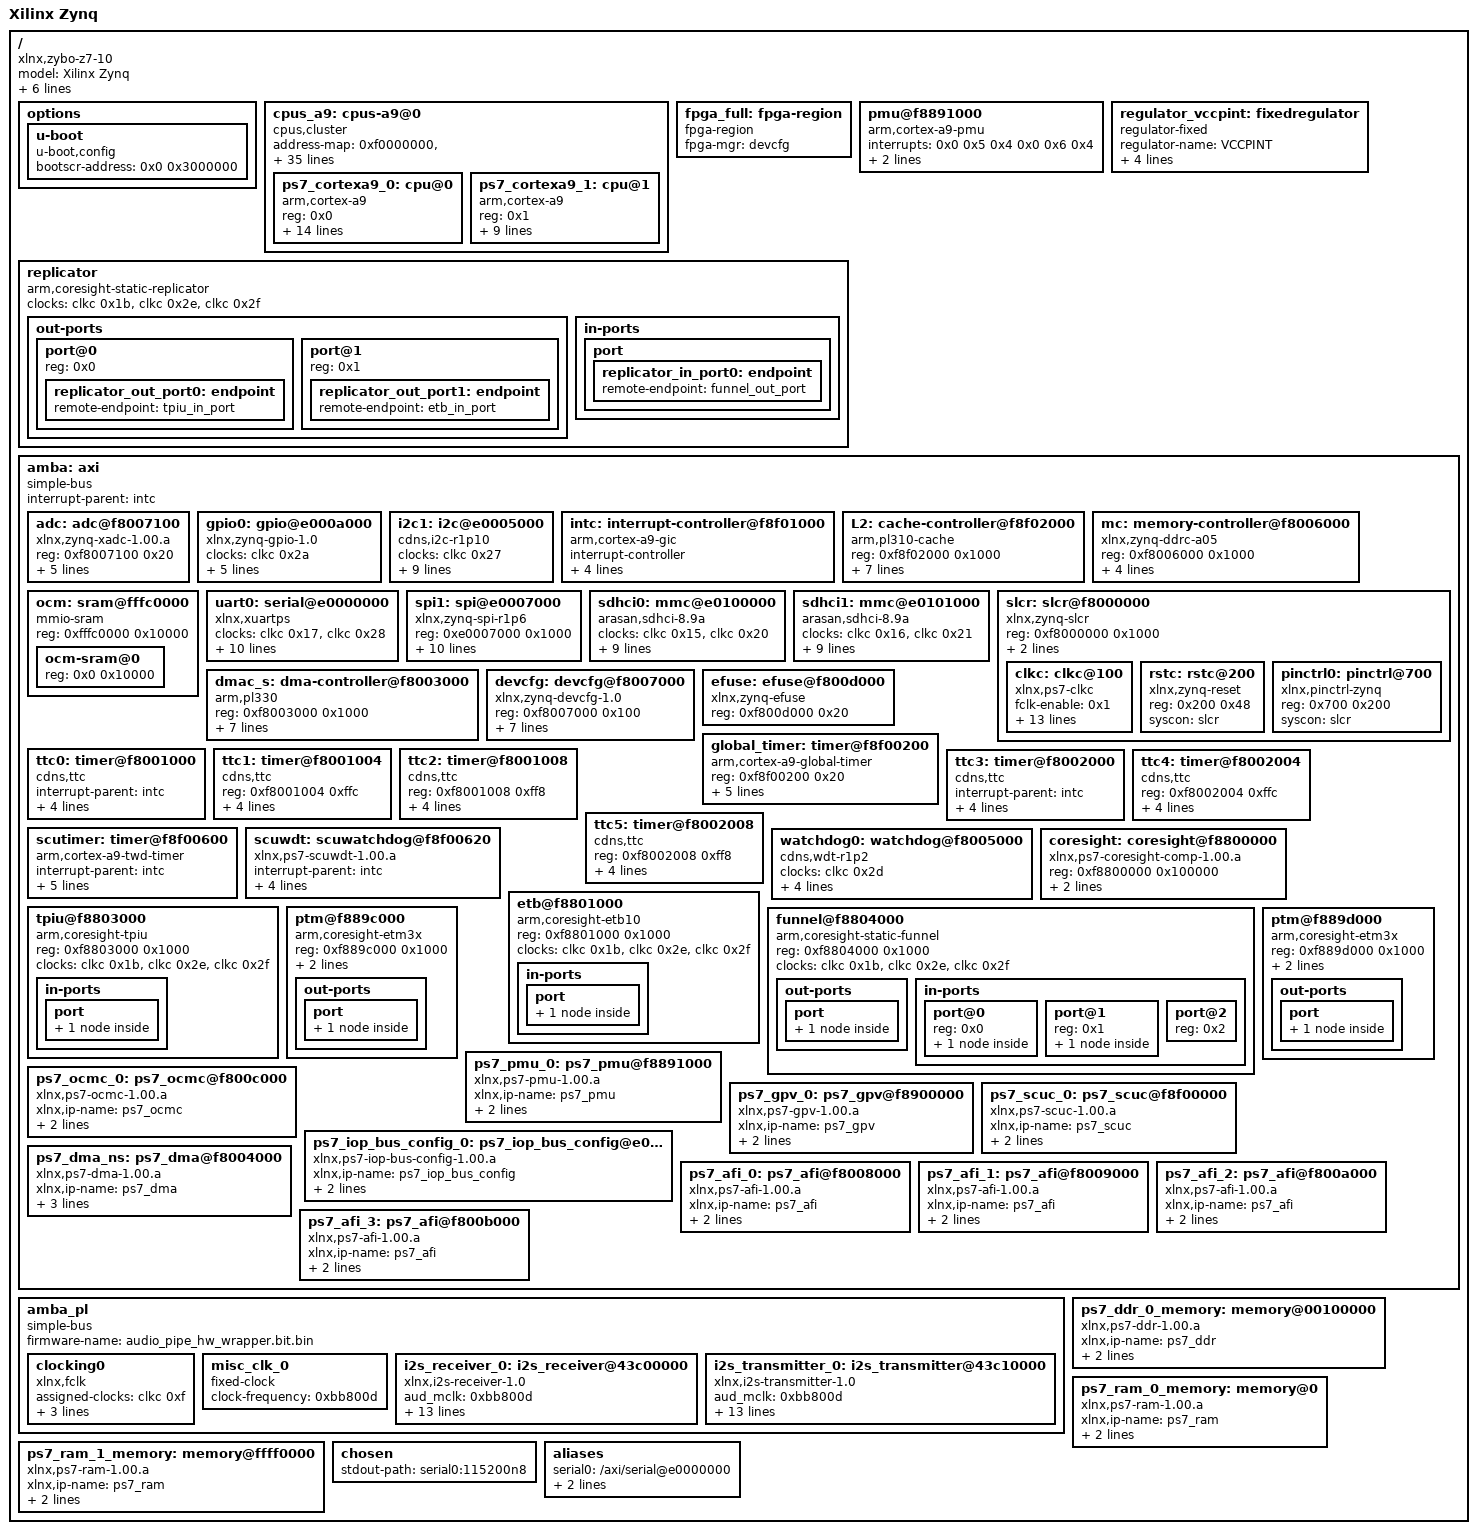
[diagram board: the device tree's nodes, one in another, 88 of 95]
/dts-v1/;
/ {
        #address-cells = <0x1>;
        #size-cells = <0x1>;
        compatible = "xlnx,zybo-z7-10";
        model = "Xilinx Zynq";
        board = "zybo-z7-10";
        device_id = "7z010";
        slrcount = <0x1>;
        family = "Zynq";
        speed_grade = "1";
        pruned-sdt = <0x1>;

        options {

                u-boot {
                        compatible = "u-boot,config";
                        bootscr-address = <0x0 0x3000000>;
                };
        };

        cpus_a9: cpus-a9@0 {
                phandle = <0x30>;
                #address-cells = <0x1>;
                #size-cells = <0x0>;
                compatible = "cpus,cluster";
                address-map = <0xf0000000 &amba 0xf0000000 0x10000000>,
                 <0x100000 &ps7_ddr_0_memory 0x100000 0x1ff00000>,
                 <0x0 &ps7_ram_0_memory 0x0 0x30000>,
                 <0xffff0000 &ps7_ram_1_memory 0xffff0000 0xfe00>,
                 <0x43c00000 &i2s_receiver_0 0x43c00000 0x10000>,
                 <0x43c10000 &i2s_transmitter_0 0x43c10000 0x10000>,
                 <0xf8008000 &ps7_afi_0 0xf8008000 0x1000>,
                 <0xf8009000 &ps7_afi_1 0xf8009000 0x1000>,
                 <0xf800a000 &ps7_afi_2 0xf800a000 0x1000>,
                 <0xf800b000 &ps7_afi_3 0xf800b000 0x1000>,
                 <0xf8800000 &coresight 0xf8800000 0x100000>,
                 <0xf8006000 &mc 0xf8006000 0x1000>,
                 <0xf8007000 &devcfg 0xf8007000 0x100>,
                 <0xf8004000 &ps7_dma_ns 0xf8004000 0x1000>,
                 <0xf8003000 &dmac_s 0xf8003000 0x1000>,
                 <0xf8f00200 &global_timer 0xf8f00200 0x100>,
                 <0xf8900000 &ps7_gpv_0 0xf8900000 0x100000>,
                 <0xe0005000 &i2c1 0xe0005000 0x1000>,
                 <0xf8f01000 &intc 0xf8f01000 0x1000>,
                 <0xe0200000 &ps7_iop_bus_config_0 0xe0200000 0x1000>,
                 <0xf8f02000 &L2 0xf8f02000 0x1000>,
                 <0xf800c000 &ps7_ocmc_0 0xf800c000 0x1000>,
                 <0xf8891000 &ps7_pmu_0 0xf8891000 0x1000>,
                 <0xf8f00000 &ps7_scuc_0 0xf8f00000 0xfd>,
                 <0xf8f00600 &scutimer 0xf8f00600 0x20>,
                 <0xf8f00620 &scuwdt 0xf8f00620 0xe0>,
                 <0xe0100000 &sdhci0 0xe0100000 0x1000>,
                 <0xe0101000 &sdhci1 0xe0101000 0x1000>,
                 <0xf8000000 &slcr 0xf8000000 0x1000>,
                 <0xe0007000 &spi1 0xe0007000 0x1000>,
                 <0xe0000000 &uart0 0xe0000000 0x1000>,
                 <0xf8007100 &adc 0xf8007100 0x21>;
                #ranges-address-cells = <0x1>;
                #ranges-size-cells = <0x1>;

                ps7_cortexa9_0: cpu@0 {
                        phandle = <0x2b>;
                        compatible = "arm,cortex-a9";
                        device_type = "cpu";
                        reg = <0x0>;
                        clocks = <&clkc 0x3>;
                        clock-latency = <0x3e8>;
                        cpu0-supply = <&regulator_vccpint>;
                        operating-points = <0xa2c2b 0xf4240 0x51616 0xf4240>;
                        xlnx,i-cache-size = <0x8000>;
                        xlnx,d-cache-line-size = <0x14>;
                        xlnx,i-cache-line-size = <0x14>;
                        xlnx,cpu-1x-clk-freq-hz = <0x69f6bcb>;
                        xlnx,ip-name = "ps7_cortexa9";
                        xlnx,d-cache-size = <0x8000>;
                        xlnx,num-cores = <0x2>;
                        xlnx,cpu-clk-freq-hz = <0x27bc86bf>;
                        bus-handle = <0x1>;
                };

                ps7_cortexa9_1: cpu@1 {
                        phandle = <0x2d>;
                        compatible = "arm,cortex-a9";
                        device_type = "cpu";
                        reg = <0x1>;
                        clocks = <&clkc 0x3>;
                        xlnx,i-cache-size = <0x8000>;
                        xlnx,d-cache-line-size = <0x14>;
                        xlnx,i-cache-line-size = <0x14>;
                        xlnx,cpu-1x-clk-freq-hz = <0x69f6bcb>;
                        xlnx,ip-name = "ps7_cortexa9";
                        xlnx,d-cache-size = <0x8000>;
                        xlnx,cpu-clk-freq-hz = <0x27bc86bf>;
                        bus-handle = <0x1>;
                };
        };

        fpga_full: fpga-region {
                phandle = <0x31>;
                compatible = "fpga-region";
                fpga-mgr = <&devcfg>;
                #address-cells = <0x1>;
                #size-cells = <0x1>;
                ranges;
        };

        pmu@f8891000 {
                compatible = "arm,cortex-a9-pmu";
                interrupts = <0x0 0x5 0x4 0x0 0x6 0x4>;
                interrupt-parent = <&intc>;
                reg = <0xf8891000 0x1000 0xf8893000 0x1000>;
        };

        regulator_vccpint: fixedregulator {
                phandle = <0x22>;
                compatible = "regulator-fixed";
                regulator-name = "VCCPINT";
                regulator-min-microvolt = <0xf4240>;
                regulator-max-microvolt = <0xf4240>;
                regulator-boot-on;
                regulator-always-on;
        };

        replicator {
                compatible = "arm,coresight-static-replicator";
                clocks = <&clkc 0x1b>,
                 <&clkc 0x2e>,
                 <&clkc 0x2f>;
                clock-names = "apb_pclk", "dbg_trc", "dbg_apb";

                out-ports {
                        #address-cells = <0x1>;
                        #size-cells = <0x0>;

                        port@0 {
                                reg = <0x0>;

                                replicator_out_port0: endpoint {
                                        phandle = <0x27>;
                                        remote-endpoint = <&tpiu_in_port>;
                                };
                        };

                        port@1 {
                                reg = <0x1>;

                                replicator_out_port1: endpoint {
                                        phandle = <0x26>;
                                        remote-endpoint = <&etb_in_port>;
                                };
                        };
                };

                in-ports {

                        port {

                                replicator_in_port0: endpoint {
                                        phandle = <0x28>;
                                        remote-endpoint = <&funnel_out_port>;
                                };
                        };
                };
        };

        amba: axi {
                phandle = <0x1>;
                bootph-all;
                compatible = "simple-bus";
                #address-cells = <0x1>;
                #size-cells = <0x1>;
                interrupt-parent = <&intc>;
                ranges;

                adc: adc@f8007100 {
                        phandle = <0x20>;
                        compatible = "xlnx,zynq-xadc-1.00.a";
                        reg = <0xf8007100 0x20>;
                        interrupts = <0x0 0x7 0x4>;
                        interrupt-parent = <&intc>;
                        clocks = <&clkc 0xc>;
                        status = "okay";
                        xlnx,ip-name = "ps7_xadc";
                        xlnx,name = "ps7_xadc_0";
                };

                gpio0: gpio@e000a000 {
                        phandle = <0x34>;
                        compatible = "xlnx,zynq-gpio-1.0";
                        #gpio-cells = <0x2>;
                        clocks = <&clkc 0x2a>;
                        gpio-controller;
                        interrupt-controller;
                        #interrupt-cells = <0x2>;
                        interrupt-parent = <&intc>;
                        interrupts = <0x0 0x14 0x4>;
                        reg = <0xe000a000 0x1000>;
                };

                i2c1: i2c@e0005000 {
                        phandle = <0x12>;
                        compatible = "cdns,i2c-r1p10";
                        status = "okay";
                        clocks = <&clkc 0x27>;
                        interrupt-parent = <&intc>;
                        interrupts = <0x0 0x30 0x4>;
                        clock-frequency = <0x61a80>;
                        reg = <0xe0005000 0x1000>;
                        #address-cells = <0x1>;
                        #size-cells = <0x0>;
                        xlnx,has-interrupt = <0x0>;
                        xlnx,clock-freq = <0x69f6bcb>;
                        xlnx,i2c-clk-freq-hz = <0x69f6bcb>;
                        xlnx,ip-name = "ps7_i2c";
                        xlnx,name = "ps7_i2c_1";
                };

                intc: interrupt-controller@f8f01000 {
                        phandle = <0x13>;
                        compatible = "arm,cortex-a9-gic";
                        #interrupt-cells = <0x3>;
                        interrupt-controller;
                        reg = <0xf8f01000 0x1000 0xf8f00100 0x100>;
                        status = "okay";
                        xlnx,irq-f2p-mode = "DIRECT";
                        xlnx,ip-name = "ps7_intc_dist";
                        xlnx,name = "ps7_intc_dist_0";
                };

                L2: cache-controller@f8f02000 {
                        phandle = <0x15>;
                        compatible = "arm,pl310-cache";
                        reg = <0xf8f02000 0x1000>;
                        interrupts = <0x0 0x2 0x4>;
                        arm,data-latency = <0x3 0x2 0x2>;
                        arm,tag-latency = <0x2 0x2 0x2>;
                        cache-unified;
                        cache-level = <0x2>;
                        status = "okay";
                        xlnx,ip-name = "ps7_pl310";
                        xlnx,name = "ps7_pl310_0";
                };

                mc: memory-controller@f8006000 {
                        phandle = <0xc>;
                        compatible = "xlnx,zynq-ddrc-a05";
                        reg = <0xf8006000 0x1000>;
                        status = "okay";
                        xlnx,ddr-clk-freq-hz = <0x1fca057e>;
                        xlnx,ip-name = "ps7_ddrc";
                        xlnx,has-ecc = <0x0>;
                        xlnx,name = "ps7_ddrc_0";
                };

                ocm: sram@fffc0000 {
                        phandle = <0x36>;
                        compatible = "mmio-sram";
                        reg = <0xfffc0000 0x10000>;
                        #address-cells = <0x1>;
                        #size-cells = <0x1>;
                        ranges = <0x0 0xfffc0000 0x10000>;

                        ocm-sram@0 {
                                reg = <0x0 0x10000>;
                        };
                };

                uart0: serial@e0000000 {
                        phandle = <0x1f>;
                        compatible = "xlnx,xuartps", "cdns,uart-r1p8";
                        status = "okay";
                        clocks = <&clkc 0x17>,
                         <&clkc 0x28>;
                        clock-names = "uart_clk", "pclk";
                        reg = <0xe0000000 0x1000>;
                        interrupts = <0x0 0x1b 0x4>;
                        interrupt-parent = <&intc>;
                        xlnx,clock-freq = <0x5f5e100>;
                        xlnx,has-modem = <0x0>;
                        xlnx,ip-name = "ps7_uart";
                        cts-override;
                        port-number = <0x0>;
                        xlnx,uart-clk-freq-hz = <0x5f5e100>;
                        xlnx,name = "ps7_uart_0";
                };

                spi1: spi@e0007000 {
                        phandle = <0x1e>;
                        compatible = "xlnx,zynq-spi-r1p6";
                        reg = <0xe0007000 0x1000>;
                        status = "okay";
                        interrupt-parent = <&intc>;
                        interrupts = <0x0 0x31 0x4>;
                        clocks = <&clkc 0x1a>,
                         <&clkc 0x23>;
                        clock-names = "ref_clk", "pclk";
                        #address-cells = <0x1>;
                        #size-cells = <0x0>;
                        xlnx,has-ss0 = <0x1>;
                        xlnx,ip-name = "ps7_spi";
                        xlnx,has-ss1 = <0x0>;
                        num-cs = <0x1>;
                        xlnx,spi-clk-freq-hz = <0x9ef21b0>;
                        xlnx,has-ss2 = <0x0>;
                        xlnx,name = "ps7_spi_1";
                };

                sdhci0: mmc@e0100000 {
                        phandle = <0x1b>;
                        compatible = "arasan,sdhci-8.9a";
                        status = "okay";
                        clock-names = "clk_xin", "clk_ahb";
                        clocks = <&clkc 0x15>,
                         <&clkc 0x20>;
                        interrupt-parent = <&intc>;
                        interrupts = <0x0 0x18 0x4>;
                        reg = <0xe0100000 0x1000>;
                        xlnx,has-power = <0x0>;
                        xlnx,ip-name = "ps7_sdio";
                        xlnx,sdio-clk-freq-hz = <0x5f5e100>;
                        xlnx,has-wp = <0x0>;
                        xlnx,has-cd = <0x0>;
                        xlnx,name = "ps7_sd_0";
                };

                sdhci1: mmc@e0101000 {
                        phandle = <0x1c>;
                        compatible = "arasan,sdhci-8.9a";
                        status = "okay";
                        clock-names = "clk_xin", "clk_ahb";
                        clocks = <&clkc 0x16>,
                         <&clkc 0x21>;
                        interrupt-parent = <&intc>;
                        interrupts = <0x0 0x2f 0x4>;
                        reg = <0xe0101000 0x1000>;
                        xlnx,has-power = <0x0>;
                        xlnx,ip-name = "ps7_sdio";
                        xlnx,sdio-clk-freq-hz = <0x5f5e100>;
                        xlnx,has-wp = <0x0>;
                        xlnx,has-cd = <0x0>;
                        xlnx,name = "ps7_sd_1";
                };

                slcr: slcr@f8000000 {
                        phandle = <0x1d>;
                        bootph-all;
                        #address-cells = <0x1>;
                        #size-cells = <0x1>;
                        compatible = "xlnx,zynq-slcr", "syscon", "simple-mfd";
                        reg = <0xf8000000 0x1000>;
                        ranges;
                        status = "okay";
                        xlnx,ip-name = "ps7_slcr";
                        xlnx,name = "ps7_slcr_0";

                        clkc: clkc@100 {
                                phandle = <0x21>;
                                bootph-all;
                                #clock-cells = <0x1>;
                                compatible = "xlnx,ps7-clkc";
                                fclk-enable = <0x1>;
                                clock-output-names = "armpll", "ddrpll", "iopll", "cpu_6or4x", "cpu_3or2x", "cpu_2x", "cpu_1x", "ddr2x", "ddr3x", "dci", "lqspi", "smc", "pcap", "gem0", "gem1", "fclk0", "fclk1", "fclk2", "fclk3", "can0", "can1", "sdio0", "sdio1", "uart0", "uart1", "spi0", "spi1", "dma", "usb0_aper", "usb1_aper", "gem0_aper", "gem1_aper", "sdio0_aper", "sdio1_aper", "spi0_aper", "spi1_aper", "can0_aper", "can1_aper", "i2c0_aper", "i2c1_aper", "uart0_aper", "uart1_aper", "gpio_aper", "lqspi_aper", "smc_aper", "swdt", "dbg_trc", "dbg_apb";
                                reg = <0x100 0x100>;
                                ps-clk-frequency = <0x1fca055>;
                        };

                        rstc: rstc@200 {
                                phandle = <0x3f>;
                                compatible = "xlnx,zynq-reset";
                                reg = <0x200 0x48>;
                                #reset-cells = <0x1>;
                                syscon = <&slcr>;
                        };

                        pinctrl0: pinctrl@700 {
                                phandle = <0x40>;
                                compatible = "xlnx,pinctrl-zynq";
                                reg = <0x700 0x200>;
                                syscon = <&slcr>;
                        };
                };

                dmac_s: dma-controller@f8003000 {
                        phandle = <0xf>;
                        compatible = "arm,pl330", "arm,primecell";
                        reg = <0xf8003000 0x1000>;
                        interrupt-parent = <&intc>;
                        interrupts = <0x0 0xd 0x4 0x0 0xe 0x4 0x0 0xf 0x4 0x0 0x10 0x4 0x0 0x11 0x4 0x0 0x28 0x4 0x0 0x29 0x4 0x0 0x2a 0x4 0x0 0x2b 0x4>;
                        #dma-cells = <0x1>;
                        clocks = <&clkc 0x1b>;
                        clock-names = "apb_pclk";
                        status = "okay";
                        xlnx,ip-name = "ps7_dma";
                        xlnx,is-secure;
                        xlnx,name = "ps7_dma_s";
                };

                devcfg: devcfg@f8007000 {
                        phandle = <0xd>;
                        compatible = "xlnx,zynq-devcfg-1.0";
                        reg = <0xf8007000 0x100>;
                        interrupt-parent = <&intc>;
                        interrupts = <0x0 0x8 0x4>;
                        clocks = <&clkc 0xc>,
                         <&clkc 0xf>,
                         <&clkc 0x10>,
                         <&clkc 0x11>,
                         <&clkc 0x12>;
                        clock-names = "ref_clk", "fclk0", "fclk1", "fclk2", "fclk3";
                        syscon = <&slcr>;
                        status = "okay";
                        xlnx,ip-name = "ps7_dev_cfg";
                        xlnx,name = "ps7_dev_cfg_0";
                };

                efuse: efuse@f800d000 {
                        phandle = <0x41>;
                        compatible = "xlnx,zynq-efuse";
                        reg = <0xf800d000 0x20>;
                };

                global_timer: timer@f8f00200 {
                        phandle = <0x10>;
                        compatible = "arm,cortex-a9-global-timer";
                        reg = <0xf8f00200 0x20>;
                        interrupts = <0x1 0xb 0x301>;
                        interrupt-parent = <&intc>;
                        clocks = <&clkc 0x4>;
                        status = "okay";
                        xlnx,ip-name = "ps7_globaltimer";
                        xlnx,name = "ps7_globaltimer_0";
                };

                ttc0: timer@f8001000 {
                        phandle = <0x42>;
                        interrupt-parent = <&intc>;
                        interrupts = <0x0 0xa 0x4 0x0 0xb 0x4 0x0 0xc 0x4>;
                        compatible = "cdns,ttc";
                        clocks = <&clkc 0x6>;
                        reg = <0xf8001000 0x1000>;
                };

                ttc1: timer@f8001004 {
                        phandle = <0x4d>;
                        reg = <0xf8001004 0xffc>;
                        clocks = <&clkc 0x6>;
                        compatible = "cdns,ttc";
                        interrupts = <0x0 0xb 0x4 0x0 0xc 0x4>;
                        interrupt-parent = <&intc>;
                        lop-dynamic-ttc-node = <0x1>;
                };

                ttc2: timer@f8001008 {
                        phandle = <0x4e>;
                        reg = <0xf8001008 0xff8>;
                        clocks = <&clkc 0x6>;
                        compatible = "cdns,ttc";
                        interrupts = <0x0 0xc 0x4>;
                        interrupt-parent = <&intc>;
                        lop-dynamic-ttc-node = <0x1>;
                };

                ttc3: timer@f8002000 {
                        phandle = <0x43>;
                        interrupt-parent = <&intc>;
                        interrupts = <0x0 0x25 0x4 0x0 0x26 0x4 0x0 0x27 0x4>;
                        compatible = "cdns,ttc";
                        clocks = <&clkc 0x6>;
                        reg = <0xf8002000 0x1000>;
                };

                ttc4: timer@f8002004 {
                        phandle = <0x4f>;
                        reg = <0xf8002004 0xffc>;
                        clocks = <&clkc 0x6>;
                        compatible = "cdns,ttc";
                        interrupts = <0x0 0x26 0x4 0x0 0x27 0x4>;
                        interrupt-parent = <&intc>;
                        lop-dynamic-ttc-node = <0x1>;
                };

                ttc5: timer@f8002008 {
                        phandle = <0x50>;
                        reg = <0xf8002008 0xff8>;
                        clocks = <&clkc 0x6>;
                        compatible = "cdns,ttc";
                        interrupts = <0x0 0x27 0x4>;
                        interrupt-parent = <&intc>;
                        lop-dynamic-ttc-node = <0x1>;
                };

                scutimer: timer@f8f00600 {
                        phandle = <0x19>;
                        bootph-all;
                        interrupt-parent = <&intc>;
                        interrupts = <0x1 0xd 0x301>;
                        compatible = "arm,cortex-a9-twd-timer";
                        reg = <0xf8f00600 0x20>;
                        clocks = <&clkc 0x4>;
                        status = "okay";
                        xlnx,ip-name = "ps7_scutimer";
                        xlnx,name = "ps7_scutimer_0";
                };

                scuwdt: scuwatchdog@f8f00620 {
                        phandle = <0x1a>;
                        interrupt-parent = <&intc>;
                        interrupts = <0x1 0xe 0x4>;
                        compatible = "xlnx,ps7-scuwdt-1.00.a";
                        reg = <0xf8f00620 0xe0>;
                        status = "okay";
                        xlnx,ip-name = "ps7_scuwdt";
                        xlnx,name = "ps7_scuwdt_0";
                };

                watchdog0: watchdog@f8005000 {
                        phandle = <0x46>;
                        clocks = <&clkc 0x2d>;
                        compatible = "cdns,wdt-r1p2";
                        interrupt-parent = <&intc>;
                        interrupts = <0x0 0x9 0x1>;
                        reg = <0xf8005000 0x1000>;
                        timeout-sec = <0xa>;
                };

                coresight: coresight@f8800000 {
                        phandle = <0xb>;
                        compatible = "xlnx,ps7-coresight-comp-1.00.a";
                        status = "okay";
                        reg = <0xf8800000 0x100000>;
                        xlnx,ip-name = "ps7_coresight_comp";
                        xlnx,name = "ps7_coresight_comp_0";
                };

                etb@f8801000 {
                        compatible = "arm,coresight-etb10", "arm,primecell";
                        reg = <0xf8801000 0x1000>;
                        clocks = <&clkc 0x1b>,
                         <&clkc 0x2e>,
                         <&clkc 0x2f>;
                        clock-names = "apb_pclk", "dbg_trc", "dbg_apb";

                        in-ports {

                                port {

                                        etb_in_port: endpoint {
                                                phandle = <0x24>;
                                                remote-endpoint = <&replicator_out_port1>;
                                        };
                                };
                        };
                };

                tpiu@f8803000 {
                        compatible = "arm,coresight-tpiu", "arm,primecell";
                        reg = <0xf8803000 0x1000>;
                        clocks = <&clkc 0x1b>,
                         <&clkc 0x2e>,
                         <&clkc 0x2f>;
                        clock-names = "apb_pclk", "dbg_trc", "dbg_apb";

                        in-ports {

                                port {

                                        tpiu_in_port: endpoint {
                                                phandle = <0x23>;
                                                remote-endpoint = <&replicator_out_port0>;
                                        };
                                };
                        };
                };

                funnel@f8804000 {
                        compatible = "arm,coresight-static-funnel", "arm,primecell";
                        reg = <0xf8804000 0x1000>;
                        clocks = <&clkc 0x1b>,
                         <&clkc 0x2e>,
                         <&clkc 0x2f>;
                        clock-names = "apb_pclk", "dbg_trc", "dbg_apb";

                        out-ports {

                                port {

                                        funnel_out_port: endpoint {
                                                phandle = <0x25>;
                                                remote-endpoint = <&replicator_in_port0>;
                                        };
                                };
                        };

                        in-ports {
                                #address-cells = <0x1>;
                                #size-cells = <0x0>;

                                port@0 {
                                        reg = <0x0>;

                                        funnel0_in_port0: endpoint {
                                                phandle = <0x2c>;
                                                remote-endpoint = <&ptm0_out_port>;
                                        };
                                };

                                port@1 {
                                        reg = <0x1>;

                                        funnel0_in_port1: endpoint {
                                                phandle = <0x2e>;
                                                remote-endpoint = <&ptm1_out_port>;
                                        };
                                };

                                port@2 {
                                        reg = <0x2>;
                                };
                        };
                };

                ptm@f889c000 {
                        compatible = "arm,coresight-etm3x", "arm,primecell";
                        reg = <0xf889c000 0x1000>;
                        clocks = <&clkc 0x1b>,
                         <&clkc 0x2e>,
                         <&clkc 0x2f>;
                        clock-names = "apb_pclk", "dbg_trc", "dbg_apb";
                        cpu = <&ps7_cortexa9_0>;

                        out-ports {

                                port {

                                        ptm0_out_port: endpoint {
                                                phandle = <0x29>;
                                                remote-endpoint = <&funnel0_in_port0>;
                                        };
                                };
                        };
                };

                ptm@f889d000 {
                        compatible = "arm,coresight-etm3x", "arm,primecell";
                        reg = <0xf889d000 0x1000>;
                        clocks = <&clkc 0x1b>,
                         <&clkc 0x2e>,
                         <&clkc 0x2f>;
                        clock-names = "apb_pclk", "dbg_trc", "dbg_apb";
                        cpu = <&ps7_cortexa9_1>;

                        out-ports {

                                port {

                                        ptm1_out_port: endpoint {
                                                phandle = <0x2a>;
                                                remote-endpoint = <&funnel0_in_port1>;
                                        };
                                };
                        };
                };

                ps7_pmu_0: ps7_pmu@f8891000 {
                        phandle = <0x17>;
                        compatible = "xlnx,ps7-pmu-1.00.a";
                        status = "okay";
                        xlnx,ip-name = "ps7_pmu";
                        reg = <0xf8891000 0x1000 0xf8893000 0x1000>;
                        xlnx,name = "ps7_pmu_0";
                };

                ps7_ocmc_0: ps7_ocmc@f800c000 {
                        phandle = <0x16>;
                        compatible = "xlnx,ps7-ocmc-1.00.a";
                        status = "okay";
                        xlnx,ip-name = "ps7_ocmc";
                        reg = <0xf800c000 0x1000>;
                        xlnx,name = "ps7_ocmc_0";
                };

                ps7_gpv_0: ps7_gpv@f8900000 {
                        phandle = <0x11>;
                        compatible = "xlnx,ps7-gpv-1.00.a";
                        status = "okay";
                        xlnx,ip-name = "ps7_gpv";
                        reg = <0xf8900000 0x100000>;
                        xlnx,name = "ps7_gpv_0";
                };

                ps7_scuc_0: ps7_scuc@f8f00000 {
                        phandle = <0x18>;
                        compatible = "xlnx,ps7-scuc-1.00.a";
                        status = "okay";
                        xlnx,ip-name = "ps7_scuc";
                        reg = <0xf8f00000 0xfd>;
                        xlnx,name = "ps7_scuc_0";
                };

                ps7_iop_bus_config_0: ps7_iop_bus_config@e0200000 {
                        phandle = <0x14>;
                        compatible = "xlnx,ps7-iop-bus-config-1.00.a";
                        status = "okay";
                        xlnx,ip-name = "ps7_iop_bus_config";
                        reg = <0xe0200000 0x1000>;
                        xlnx,name = "ps7_iop_bus_config_0";
                };

                ps7_dma_ns: ps7_dma@f8004000 {
                        phandle = <0xe>;
                        compatible = "xlnx,ps7-dma-1.00.a";
                        status = "okay";
                        xlnx,ip-name = "ps7_dma";
                        xlnx,is-secure;
                        reg = <0xf8004000 0x1000>;
                        xlnx,name = "ps7_dma_ns";
                };

                ps7_afi_0: ps7_afi@f8008000 {
                        phandle = <0x7>;
                        compatible = "xlnx,ps7-afi-1.00.a";
                        status = "okay";
                        xlnx,ip-name = "ps7_afi";
                        reg = <0xf8008000 0x1000>;
                        xlnx,name = "ps7_afi_0";
                };

                ps7_afi_1: ps7_afi@f8009000 {
                        phandle = <0x8>;
                        compatible = "xlnx,ps7-afi-1.00.a";
                        status = "okay";
                        xlnx,ip-name = "ps7_afi";
                        reg = <0xf8009000 0x1000>;
                        xlnx,name = "ps7_afi_1";
                };

                ps7_afi_2: ps7_afi@f800a000 {
                        phandle = <0x9>;
                        compatible = "xlnx,ps7-afi-1.00.a";
                        status = "okay";
                        xlnx,ip-name = "ps7_afi";
                        reg = <0xf800a000 0x1000>;
                        xlnx,name = "ps7_afi_2";
                };

                ps7_afi_3: ps7_afi@f800b000 {
                        phandle = <0xa>;
                        compatible = "xlnx,ps7-afi-1.00.a";
                        status = "okay";
                        xlnx,ip-name = "ps7_afi";
                        reg = <0xf800b000 0x1000>;
                        xlnx,name = "ps7_afi_3";
                };
        };

        amba_pl: amba_pl {
                phandle = <0x4b>;
                ranges;
                compatible = "simple-bus";
                #address-cells = <0x1>;
                #size-cells = <0x1>;
                firmware-name = "audio_pipe_hw_wrapper.bit.bin";

                clocking0: clocking0 {
                        phandle = <0x4c>;
                        compatible = "xlnx,fclk";
                        assigned-clocks = <&clkc 0xf>;
                        assigned-clock-rates = <0x2faf080>;
                        #clock-cells = <0x0>;
                        clock-output-names = "fabric_clk";
                        clocks = <&clkc 0xf>;
                };

                misc_clk_0: misc_clk_0 {
                        phandle = <0x2f>;
                        compatible = "fixed-clock";
                        clock-frequency = <0xbb800d>;
                        #clock-cells = <0x0>;
                };

                i2s_receiver_0: i2s_receiver@43c00000 {
                        phandle = <0x5>;
                        aud_mclk = <0xbb800d>;
                        interrupts = <0x0 0x1d 0x4>;
                        compatible = "xlnx,i2s-receiver-1.0", "xlnx,i2s-receiver-1.0";
                        xlnx,dwidth = <0x18>;
                        xlnx,depth = <0x80>;
                        interrupt-parent = <&intc>;
                        xlnx,ip-name = "i2s_receiver";
                        reg = <0x43c00000 0x10000>;
                        clocks = <&misc_clk_0>,
                         <&clkc 0xf>,
                         <&clkc 0xf>;
                        xlnx,num-channels = <0x1>;
                        xlnx,i2srx-board-interface = "Custom";
                        xlnx,edk-iptype = "PERIPHERAL";
                        xlnx,is-master = <0x1>;
                        status = "okay";
                        clock-names = "aud_mclk", "m_axis_aud_aclk", "s_axi_ctrl_aclk";
                        xlnx,32bit-lr = <0x0>;
                        interrupt-names = "irq";
                        xlnx,name = "i2s_receiver_0";
                };

                i2s_transmitter_0: i2s_transmitter@43c10000 {
                        phandle = <0x6>;
                        aud_mclk = <0xbb800d>;
                        interrupts = <0x0 0x1e 0x4>;
                        compatible = "xlnx,i2s-transmitter-1.0", "xlnx,i2s-transmitter-1.0";
                        xlnx,dwidth = <0x18>;
                        xlnx,depth = <0x80>;
                        interrupt-parent = <&intc>;
                        xlnx,ip-name = "i2s_transmitter";
                        reg = <0x43c10000 0x10000>;
                        clocks = <&misc_clk_0>,
                         <&clkc 0xf>,
                         <&clkc 0xf>;
                        xlnx,num-channels = <0x1>;
                        xlnx,edk-iptype = "PERIPHERAL";
                        xlnx,is-master = <0x0>;
                        xlnx,i2stx-board-interface = "Custom";
                        status = "okay";
                        clock-names = "aud_mclk", "s_axi_ctrl_aclk", "s_axis_aud_aclk";
                        xlnx,32bit-lr = <0x0>;
                        interrupt-names = "irq";
                        xlnx,name = "i2s_transmitter_0";
                };
        };

        ps7_ddr_0_memory: memory@00100000 {
                phandle = <0x2>;
                compatible = "xlnx,ps7-ddr-1.00.a";
                xlnx,ip-name = "ps7_ddr";
                device_type = "memory";
                memory_type = "memory";
                reg = <0x100000 0x1ff00000>;
        };

        ps7_ram_0_memory: memory@0 {
                phandle = <0x3>;
                compatible = "xlnx,ps7-ram-1.00.a";
                xlnx,ip-name = "ps7_ram";
                device_type = "memory";
                memory_type = "memory";
                reg = <0x0 0x30000>;
        };

        ps7_ram_1_memory: memory@ffff0000 {
                phandle = <0x4>;
                compatible = "xlnx,ps7-ram-1.00.a";
                xlnx,ip-name = "ps7_ram";
                device_type = "memory";
                memory_type = "memory";
                reg = <0xffff0000 0xfe00>;
        };

        chosen {
                stdout-path = "serial0:115200n8";
        };

        aliases {
                serial0 = "/axi/serial@e0000000";
                serial1 = "/axi/coresight@f8800000";
                i2c0 = "/axi/i2c@e0005000";
        };

        __symbols__ {
                cpus_a9 = "/cpus-a9@0";
                ps7_cortexa9_0 = "/cpus-a9@0/cpu@0";
                ps7_cortexa9_1 = "/cpus-a9@0/cpu@1";
                fpga_full = "/fpga-region";
                regulator_vccpint = "/fixedregulator";
                replicator_out_port0 = "/replicator/out-ports/port@0/endpoint";
                replicator_out_port1 = "/replicator/out-ports/port@1/endpoint";
                replicator_in_port0 = "/replicator/in-ports/port/endpoint";
                amba = "/axi";
                adc = "/axi/adc@f8007100";
                gpio0 = "/axi/gpio@e000a000";
                i2c1 = "/axi/i2c@e0005000";
                intc = "/axi/interrupt-controller@f8f01000";
                L2 = "/axi/cache-controller@f8f02000";
                mc = "/axi/memory-controller@f8006000";
                ocm = "/axi/sram@fffc0000";
                uart0 = "/axi/serial@e0000000";
                spi1 = "/axi/spi@e0007000";
                sdhci0 = "/axi/mmc@e0100000";
                sdhci1 = "/axi/mmc@e0101000";
                slcr = "/axi/slcr@f8000000";
                clkc = "/axi/slcr@f8000000/clkc@100";
                rstc = "/axi/slcr@f8000000/rstc@200";
                pinctrl0 = "/axi/slcr@f8000000/pinctrl@700";
                dmac_s = "/axi/dma-controller@f8003000";
                devcfg = "/axi/devcfg@f8007000";
                efuse = "/axi/efuse@f800d000";
                global_timer = "/axi/timer@f8f00200";
                scutimer = "/axi/timer@f8f00600";
                scuwdt = "/axi/scuwatchdog@f8f00620";
                watchdog0 = "/axi/watchdog@f8005000";
                coresight = "/axi/coresight@f8800000";
                etb_in_port = "/axi/etb@f8801000/in-ports/port/endpoint";
                tpiu_in_port = "/axi/tpiu@f8803000/in-ports/port/endpoint";
                funnel_out_port = "/axi/funnel@f8804000/out-ports/port/endpoint";
                funnel0_in_port0 = "/axi/funnel@f8804000/in-ports/port@0/endpoint";
                funnel0_in_port1 = "/axi/funnel@f8804000/in-ports/port@1/endpoint";
                ptm0_out_port = "/axi/ptm@f889c000/out-ports/port/endpoint";
                ptm1_out_port = "/axi/ptm@f889d000/out-ports/port/endpoint";
                ps7_pmu_0 = "/axi/ps7_pmu@f8891000";
                ps7_ocmc_0 = "/axi/ps7_ocmc@f800c000";
                ps7_gpv_0 = "/axi/ps7_gpv@f8900000";
                ps7_scuc_0 = "/axi/ps7_scuc@f8f00000";
                ps7_iop_bus_config_0 = "/axi/ps7_iop_bus_config@e0200000";
                ps7_dma_ns = "/axi/ps7_dma@f8004000";
                ps7_afi_0 = "/axi/ps7_afi@f8008000";
                ps7_afi_1 = "/axi/ps7_afi@f8009000";
                ps7_afi_2 = "/axi/ps7_afi@f800a000";
                ps7_afi_3 = "/axi/ps7_afi@f800b000";
                amba_pl = "/amba_pl";
                clocking0 = "/amba_pl/clocking0";
                misc_clk_0 = "/amba_pl/misc_clk_0";
                i2s_receiver_0 = "/amba_pl/i2s_receiver@43c00000";
                i2s_transmitter_0 = "/amba_pl/i2s_transmitter@43c10000";
                ps7_ddr_0_memory = "/memory@00100000";
                ps7_ram_0_memory = "/memory@0";
                ps7_ram_1_memory = "/memory@ffff0000";
        };
};
